VERSION ""

NS_ :

BS_:

BU_: ECU TCU

BO_ 640 EngineData: 8 ECU
 SG_ EngineRPM : 24|16@1+ (0.25,0) [0|8000] "rpm" Vector__XXX
 SG_ EngineLoad : 8|8@1+ (0.392,0) [0|100] "%" Vector__XXX

BO_ 800 CoolantTemp: 8 ECU
 SG_ CoolantTemp : 0|8@1+ (1,-40) [-40|215] "degC" Vector__XXX

BO_ 896 VehicleSpeed: 8 ECU
 SG_ VehicleSpeed : 0|16@1+ (0.01,0) [0|300] "km/h" Vector__XXX

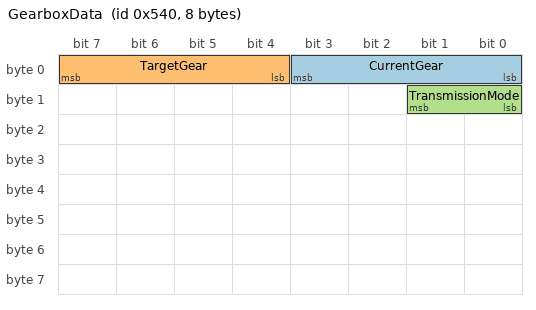
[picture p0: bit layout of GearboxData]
BO_ 1344 GearboxData: 8 TCU
 SG_ CurrentGear : 0|4@1+ (1,0) [0|8] "" Vector__XXX
 SG_ TargetGear : 4|4@1+ (1,0) [0|8] "" Vector__XXX
 SG_ TransmissionMode : 8|2@1+ (1,0) [0|3] "" Vector__XXX

BO_ 1376 GearboxOilTemp: 8 TCU
 SG_ GearboxOilTemp : 0|8@1+ (1,-40) [-40|215] "degC" Vector__XXX

BO_ 1408 ShiftLeverPosition: 8 TCU
 SG_ ShiftLeverPosition : 0|8@1+ (1,0) [0|255] "" Vector__XXX
